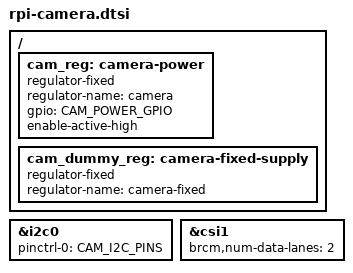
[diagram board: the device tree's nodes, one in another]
// SPDX-License-Identifier: GPL-2.0
// The camera connector's wiring, which differs between the boards: the
// I2C pins the camera is controlled through (`CAM_I2C_PINS`, on i2c0) and
// the line that powers it (`CAM_POWER_GPIO`). Unicam's CSI-2 port 1 takes
// its pictures, over two lanes. The camera itself (which sensor, its clock)
// comes in an overlay from boot/overlays/, which the firmware applies when
// it finds one (camera_auto_detect in config.txt). The labels here are what
// the overlays refer to. (From the Raspberry Pi kernel's device trees.)

/ {
	cam_reg: camera-power {
		compatible = "regulator-fixed";
		regulator-name = "camera";
		gpio = CAM_POWER_GPIO;
		enable-active-high;
	};

	// The sensors' other supplies come from the board, always on.
	cam_dummy_reg: camera-fixed-supply {
		compatible = "regulator-fixed";
		regulator-name = "camera-fixed";
	};
};

// i2c0 serves only the camera (Dazzle does not read HAT EEPROMs).
&i2c0 {
	pinctrl-0 = <CAM_I2C_PINS>;
};

&csi1 {
	brcm,num-data-lanes = <2>;
};
